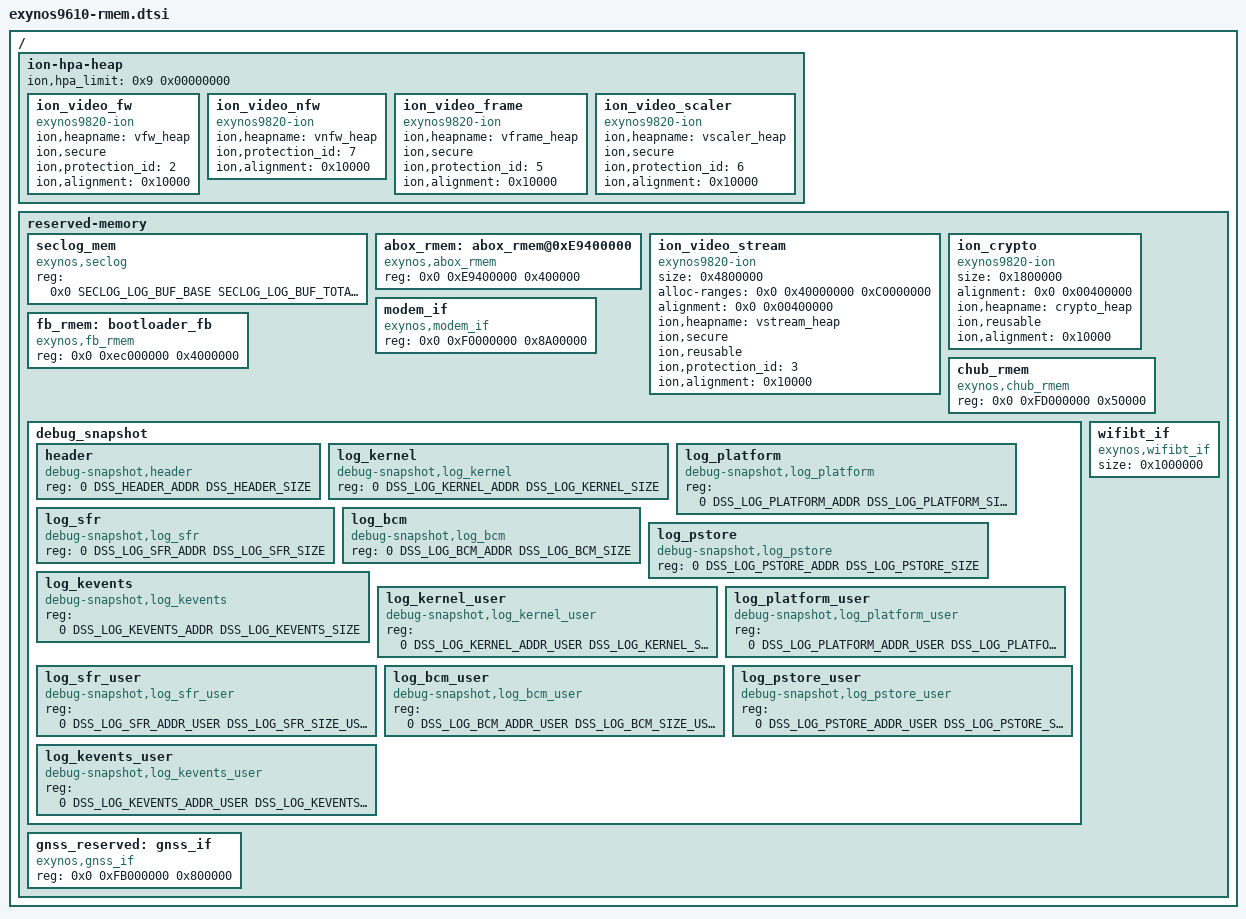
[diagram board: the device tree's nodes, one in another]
/*
 * SAMSUNG EXYNOS device tree source for reserved-memory
 *
 * Copyright (c) 2015 Samsung Electronics Co., Ltd.
 *		http://www.samsung.com
 *
 * This program is free software; you can redistribute it and/or modify
 * it under the terms of the GNU General Public License version 2 as
 * published by the Free Software Foundation.
 */

#include <dt-bindings/soc/samsung/debug-snapshot-table.h>
#include <dt-bindings/soc/samsung/exynos9610-seclog.h>

/ {
	ion-hpa-heap {
		#address-cells = <2>;
		#size-cells = <1>;
		ranges;
		ion,hpa_limit = <0x9 0x00000000>;
		ion_video_fw {
			compatible = "exynos9820-ion";
			ion,heapname = "vfw_heap";
			ion,secure;
			ion,protection_id = <2>;
			ion,alignment = <0x10000>;
		};

		ion_video_nfw {
			compatible = "exynos9820-ion";
			ion,heapname = "vnfw_heap";
			ion,protection_id = <7>;
			ion,alignment = <0x10000>;
		};

		ion_video_frame {
			compatible = "exynos9820-ion";
			ion,heapname = "vframe_heap";
			ion,secure;
			ion,protection_id = <5>;
			ion,alignment = <0x10000>;
		};

		ion_video_scaler {
			compatible = "exynos9820-ion";
			ion,heapname = "vscaler_heap";
			ion,secure;
			ion,protection_id = <6>;
			ion,alignment = <0x10000>;
		};
	};

	reserved-memory {
		#address-cells = <2>;
		#size-cells = <1>;
		ranges;

		seclog_mem {
			compatible = "exynos,seclog";
			reg = <0x0 SECLOG_LOG_BUF_BASE SECLOG_LOG_BUF_TOTAL_SIZE>;
		};

		abox_rmem: abox_rmem@0xE9400000 {
                        compatible = "exynos,abox_rmem";
                        reg = <0x0 0xE9400000 0x400000>;
                };

		ion_video_stream {
			compatible = "exynos9820-ion";
			size = <0x4800000>;
			alloc-ranges = <0x0 0x40000000 0xC0000000>;
			alignment = <0x0 0x00400000>;
			ion,heapname = "vstream_heap";
			ion,secure;
			ion,reusable;
			ion,protection_id = <3>;
			ion,alignment = <0x10000>;
		};

		ion_crypto {
			compatible = "exynos9820-ion";
			size = <0x1800000>;
			alignment = <0x0 0x00400000>;
			ion,heapname = "crypto_heap";
			ion,reusable;
			ion,alignment = <0x10000>;
		};

		modem_if {
			compatible = "exynos,modem_if";
			reg = <0x0 0xF0000000 0x8A00000>;
		};

		fb_rmem: bootloader_fb {
			compatible = "exynos,fb_rmem";
			reg = <0x0 0xec000000 0x4000000>;
		};

		chub_rmem: chub_rmem {
			compatible = "exynos,chub_rmem";
			/* To dump SHUB SRAM out upon shub firmware crash */
			reg = <0x0 0xFD000000 0x50000>;
		};

		debug_snapshot {
			#address-cells = <2>;
			#size-cells = <1>;
			/* If this property exist, these are modified by bootloader. */

			header {
				compatible = "debug-snapshot,header";
				reg = <0 DSS_HEADER_ADDR DSS_HEADER_SIZE>;
			};

			log_kernel {
				compatible = "debug-snapshot,log_kernel";
				reg = <0 DSS_LOG_KERNEL_ADDR DSS_LOG_KERNEL_SIZE>;
			};

			log_platform {
				compatible = "debug-snapshot,log_platform";
				reg = <0 DSS_LOG_PLATFORM_ADDR DSS_LOG_PLATFORM_SIZE>;
			};

			log_sfr {
				compatible = "debug-snapshot,log_sfr";
				reg = <0 DSS_LOG_SFR_ADDR DSS_LOG_SFR_SIZE>;
			};

			log_bcm {
				compatible = "debug-snapshot,log_bcm";
				reg = <0 DSS_LOG_BCM_ADDR DSS_LOG_BCM_SIZE>;
			};

			log_pstore {
				compatible = "debug-snapshot,log_pstore";
				reg = <0 DSS_LOG_PSTORE_ADDR DSS_LOG_PSTORE_SIZE>;
			};

			log_kevents {
				compatible = "debug-snapshot,log_kevents";
				reg = <0 DSS_LOG_KEVENTS_ADDR DSS_LOG_KEVENTS_SIZE>;
			};

			log_kernel_user {
				compatible = "debug-snapshot,log_kernel_user";
				reg = <0 DSS_LOG_KERNEL_ADDR_USER DSS_LOG_KERNEL_SIZE_USER>;
			};

			log_platform_user {
				compatible = "debug-snapshot,log_platform_user";
				reg = <0 DSS_LOG_PLATFORM_ADDR_USER DSS_LOG_PLATFORM_SIZE_USER>;
			};

			log_sfr_user {
				compatible = "debug-snapshot,log_sfr_user";
				reg = <0 DSS_LOG_SFR_ADDR_USER DSS_LOG_SFR_SIZE_USER>;
			};

			log_bcm_user {
				compatible = "debug-snapshot,log_bcm_user";
				reg = <0 DSS_LOG_BCM_ADDR_USER DSS_LOG_BCM_SIZE_USER>;
			};

			log_pstore_user {
				compatible = "debug-snapshot,log_pstore_user";
				reg = <0 DSS_LOG_PSTORE_ADDR_USER DSS_LOG_PSTORE_SIZE_USER>;
			};

			log_kevents_user {
				compatible = "debug-snapshot,log_kevents_user";
				reg = <0 DSS_LOG_KEVENTS_ADDR_USER DSS_LOG_KEVENTS_SIZE_USER>;
			};
		};

		gnss_reserved: gnss_if {
			compatible = "exynos,gnss_if";
			reg = <0x0 0xFB000000 0x800000>;
		};

		wifibt_if {
			compatible = "exynos,wifibt_if";
			size = <0x1000000>; /* 16MB */
		};
	};
};
